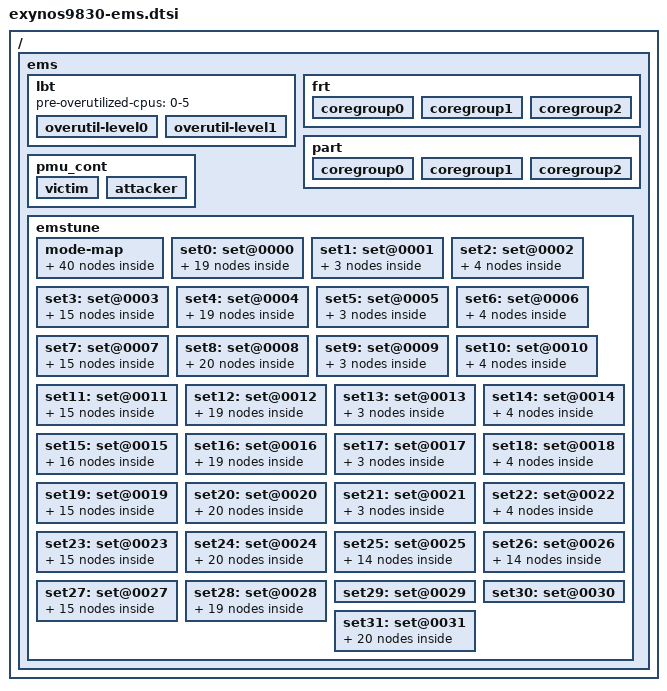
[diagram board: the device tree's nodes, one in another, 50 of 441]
/*
 * SAMSUNG EXYNOS SoC EMS device tree source
 *
 * Copyright (c) 2019 Samsung Electronics Co., Ltd.
 *             http://www.samsung.com
 *
 * SAMSUNG EXYNOS SoC EMS device nodes are listed in this file.
 * EXYNOS based board files should include this file.
 *
 * This program is free software; you can redistribute it and/or modify
 * it under the terms of the GNU General Public License version 2 as
 * published by the Free Software Foundation.
 *
 */
#include <dt-bindings/soc/samsung/ems.h>

/ {
	ems {
		/* Load Balance Trigger */
		#define DEFAULT_RATIO	80
		lbt {
			pre-overutilized-cpus = "0-5";

			overutil-level0 {
				cpus =	"0-3",
					"4-5",
					"6-7";
				ratio =	<25>,
					<25>,
					<30>;
			};
			overutil-level1 {
				cpus = "0-7";
				ratio = <DEFAULT_RATIO>;
			};
		};

		/* FRT Migration */
		frt {
			/* little cores */
			coregroup0 {
				coverage-ratio = <30>;
				active-ratio = <25>;
			};
			/* middle cores */
			coregroup1 {
				coverage-ratio = <30>;
				active-ratio = <100>;
			};
			/* big cores */
			coregroup2 {
				coverage-ratio = <30>;
				active-ratio = <100>;
			};
		};

		part {
			/* little cores */
			coregroup0 {
				active-ratio-limit = <43>;
				active-ratio-boost = <42>;
			};
			/* middle cores */
			coregroup1 {
				active-ratio-limit = <48>;
				active-ratio-boost = <35>;
			};
			/* big cores */
			coregroup2 {
				active-ratio-limit = <30>;
				active-ratio-boost = <0>;
			};
		};

		pmu_cont {
			victim_cpus = "4-5";
			attacker_cpus = "6-7";
			contention_cpus = "0-5";
			attacker_search_timout_msec = <32>;

			victim {
				search_hist_size = <4>;
				event_thr = <850>;
				active_thr = <700>;
			};
			attacker {
				search_hist_size = <1>;
				event_thr = <10>;
				active_thr = <850>;
			};

		};

		emstune {
			mode-map {
				mode0 {
					desc = "normal";
					boost_level = <3>;

					level0 {
						set = <&set0>;
					};
					level1 {
						set = <&set1>;
					};
					level2 {
						set = <&set2>;
					};
					level3 {
						set = <&set3>;
					};
				};
				mode1 {
					desc = "power-scenario";
					boost_level = <3>;

					level0 {
						set = <&set4>;
					};
					level1 {
						set = <&set5>;
					};
					level2 {
						set = <&set6>;
					};
					level3 {
						set = <&set7>;
					};
				};
				mode2 {
					desc = "performance";
					boost_level = <3>;

					level0 {
						set = <&set8>;
					};
					level1 {
						set = <&set9>;
					};
					level2 {
						set = <&set10>;
					};
					level3 {
						set = <&set11>;
					};
				};
				mode3 {
					desc = "light-game";
					boost_level = <3>;

					level0 {
						set = <&set12>;
					};
					level1 {
						set = <&set13>;
					};
					level2 {
						set = <&set14>;
					};
					level3 {
						set = <&set15>;
					};
				};
				mode4 {
					desc = "light-video";
					boost_level = <3>;

					level0 {
						set = <&set16>;
					};
					level1 {
						set = <&set17>;
					};
					level2 {
						set = <&set18>;
					};
					level3 {
						set = <&set19>;
					};
				};
				mode5 {
					desc = "balance";
					boost_level = <3>;

					level0 {
						set = <&set20>;
					};
					level1 {
						set = <&set21>;
					};
					level2 {
						set = <&set22>;
					};
					level3 {
						set = <&set23>;
					};
				};
				mode6 {
					desc = "pinned";
					boost_level = <3>;

					level0 {
						set = <&set24>;
					};
					level1 {
						set = <&set25>;
					};
					level2 {
						set = <&set26>;
					};
					level3 {
						set = <&set27>;
					};
				};
				mode7 {
					desc = "game-mode";
					boost_level = <3>;

					level0 {
						set = <&set28>;
					};
					level1 {
						set = <&set29>;
					};
					level2 {
						set = <&set30>;
					};
					level3 {
						set = <&set31>;
					};
				};

			};

			set0: set@0000{
				idx = <0>;
				desc = "normal default";

				sched_policy {
					policy  = <SCHED_POLICY_EFF		/* root */
						   SCHED_POLICY_EFF		/* fg */
						   SCHED_POLICY_EFF		/* bg */
						   SCHED_POLICY_EFF		/* ta */
						   SCHED_POLICY_EFF>;		/* rt */
				};

				/* weight (%) applied to active cpu's efficiency */
				weight {           /* cpu    0   1   2   3   4   5   6   7 */
					root            = <100 100 100 100 200 200  20  25>;
					foreground      = <100 100 100 100 200 200  20  25>;
					background      = <100 100 100 100 200 200  20  25>;
					top-app         = <100 100 100 100 200 200  20  25>;
					rt              = <100 100 100 100 200 200  20  25>;
				};

				/* weight (%) applied to idle cpu's efficiency */
				idle_weight {      /* cpu    0   1   2   3   4   5   6   7 */
					root            = <200 200 200 200 400 400  40  50>;
					foreground      = <200 200 200 200 400 400  40  50>;
					background      = <200 200 200 200 400 400  40  50>;
					top-app         = <200 200 200 200 400 400  40  50>;
					rt              = <200 200 200 200 400 400  40  50>;
				};

				/* Boosting margin applied to frequency selection */
				freq_boost {       /* cpu    0  1  2  3  4  5  6  7 */
					root            = <  0  0  0  0  0  0  0  0 >;
					foreground      = <  0  0  0  0  0  0  0  0 >;
					background      = <  0  0  0  0  0  0  0  0 >;
					top-app         = <  5  5  5  5  5  5  5  5 >;
					rt              = <  0  0  0  0  0  0  0  0 >;
				};

				/* cpus allowed applied to core selection */
				cpus_allowed {
					target-sched-class = <EMS_SCHED_FAIR>;

					root		= "0-7";
					foreground 	= "0-7";
					background	= "0-7";
					top-app		= "0-7";
					rt		= "0-7";
				};

				/* gov-data used by CPUFreq governor */
				esg {			/* LIT MED BIG */
					step		= <  4   6   8 >;
					patient_mode	= <  0   0   0 >;
				};

				/* Ontime Migration */
				ontime {        /* root fg bg ta rt */
					enabled  = <  0  1  0  1  0  >;

					dom_list_u {
						domain0 {
							cpus = "0-3";
							lower-boundary = <0>;
							upper-boundary = <105>;
						};
						domain1 {
							cpus = "4-5";
							lower-boundary = <106>;
							upper-boundary = <586>;
						};
						domain2 {
							cpus = "6-7";
							lower-boundary = <205>;
							upper-boundary = <1024>;
						};
					};
					dom_list_s {
						domain0 {
							cpus = "0-3";
							lower-boundary = <0>;
							upper-boundary = <51>;
						};
						domain1 {
							cpus = "4-7";
							lower-boundary = <41>;
							upper-boundary = <1024>;
						};
					};
				};
				util_est {	/* root fg bg ta rt */
					enabled  = <  0  1  0  1  0  >;
				};

				prio_pinning {	/* root fg bg ta rt */
					enabled  = <  0  0  0  0  0  >;

					mask = "6-7";
					prio = <110>;
				};

				init_util {	/* root fg bg ta rt */
					ratio  = <   25 25 25 25 25  >;
				};

				frt {	   		/* LIT MED BIG */
					coverage_ratio =  < 30  30  30>;
					active_ratio =	  < 25 100 100>;
				};

				migov {
					migov_en = < 0 >;
				};
			};

			set1: set@0001{
				idx = <1>;
				desc = "normal med boost";

				/* weight (%) applied to active cpu's efficiency */
				weight {           /* cpu    0   1   2   3   4   5   6   7 */
					root            = <100 100 100 100 200 200  20  25>;
					foreground      = < 50  50  50  50 150 150 100 106>;
					background      = <100 100 100 100 200 200  20  25>;
					top-app         = < 50  50  50  50 150 150 100 106>;
					rt              = <100 100 100 100 200 200  20  25>;
				};

				/* weight (%) applied to idle cpu's efficiency */
				idle_weight {      /* cpu    0   1   2   3   4   5   6   7 */
					root            = <200 200 200 200 400 400  40  50>;
					foreground      = <200 200 200 200 7600 7600 3800 4028>;
					background      = <200 200 200 200 400 400  40  50>;
					top-app         = <200 200 200 200 7600 7600 3800 4028>;
					rt              = <200 200 200 200 400 400  40  50>;
				};

				/* Boosting margin applied to frequency selection */
				freq_boost {       /* cpu    0  1  2  3  4  5  6  7 */
					root            = <  0  0  0  0  0  0  0  0 >;
					foreground      = <  0  0  0  0  0  0  0  0 >;
					background      = <  0  0  0  0  0  0  0  0 >;
					top-app         = <  5  5  5  5  5  5  5  5 >;
					rt              = <  0  0  0  0  0  0  0  0 >;
				};
			};

			set2: set@0002{
				idx = <2>;
				desc = "normal touch boost";

				/* weight (%) applied to active cpu's efficiency */
				weight {           /* cpu    0   1   2   3   4   5   6   7 */
					root            = <100 100 100 100 200 200  20  25>;
					foreground      = < 50  50  50  50 150 150 100 106>;
					background      = <100 100 100 100 200 200  20  25>;
					top-app         = < 50  50  50  50 150 150 100 106>;
					rt              = <100 100 100 100 200 200  20  25>;
				};

				/* weight (%) applied to idle cpu's efficiency */
				idle_weight {      /* cpu    0   1   2   3   4   5   6   7 */
					root            = <200 200 200 200 400 400  40  50>;
					foreground      = <200 200 200 200 7600 7600 3800 4028>;
					background      = <200 200 200 200 400 400  40  50>;
					top-app         = <200 200 200 200 7600 7600 3800 4028>;
					rt              = <200 200 200 200 400 400  40  50>;
				};

				/* Boosting margin applied to frequency selection */
				freq_boost {       /* cpu    0  1  2  3  4  5  6  7 */
					root            = <  0  0  0  0  0  0  0  0 >;
					foreground      = <  0  0  0  0  0  0  0  0 >;
					background      = <  0  0  0  0  0  0  0  0 >;
					top-app         = < 20 20 20 20 20 20 20 20 >;
					rt              = <  0  0  0  0  0  0  0  0 >;
				};

				frt {	   		/* LIT MED BIG */
					coverage_ratio =  < 30  30  30>;
					active_ratio =	  < 25   3   5>;
				};
			};

			set3: set@0003{
				idx = <3>;
				desc = "normal big boost";

				sched_policy {
					policy  = <SCHED_POLICY_EFF		/* root */
						   SCHED_POLICY_PERF		/* fg */
						   SCHED_POLICY_EFF		/* bg */
						   SCHED_POLICY_PERF		/* ta */
						   SCHED_POLICY_EFF>;		/* rt */
				};

				/* weight (%) applied to active cpu's efficiency */
				weight {           /* cpu    0   1   2   3   4   5   6   7 */
					root            = <100 100 100 100 100 100 100 100>;
					foreground      = <100 100 100 100 200 200 300 300>;
					background      = <100 100 100 100 100 100 100 100>;
					top-app         = <100 100 100 100 200 200 300 300>;
					rt              = <100 100 100 100 200 200 100 100>;
				};

				/* Boosting margin applied to frequency selection */
				freq_boost {       /* cpu    0  1  2  3  4  5  6  7 */
					root            = <  0  0  0  0  0  0  0  0 >;
					foreground      = <  0  0  0  0  0  0  0  0 >;
					background      = <  0  0  0  0  0  0  0  0 >;
					top-app         = <  5  5  5  5  5  5  5  5 >;
					rt              = <  0  0  0  0  0  0  0  0 >;
				};

				/* Ontime Migration */
				ontime {        /* root fg bg ta rt */
					enabled  = <  0  1  0  1  0  >;

					dom_list_u {
						domain0 {
							cpus = "0-3";
							lower-boundary = <0>;
							upper-boundary = <105>;
						};
						domain1 {
							cpus = "4-5";
							lower-boundary = <106>;
							upper-boundary = <586>;
						};
						domain2 {
							cpus = "6-7";
							lower-boundary = <205>;
							upper-boundary = <1024>;
						};

					};
					dom_list_s {
						domain0 {
							cpus = "0-3";
							lower-boundary = <0>;
							upper-boundary = <51>;
						};
						domain1 {
							cpus = "4-5";
							lower-boundary = <41>;
							upper-boundary = <344>;
						};
						domain2 {
							cpus = "6-7";
							lower-boundary = <300>;
							upper-boundary = <1024>;
						};
					};
				};

				prio_pinning {	/* root fg bg ta rt */
					enabled  = <  0  1  0  1  0  >;

					mask = "6-7";
					prio = <110>;
				};

				init_util {	/* root fg bg ta rt */
					ratio  = <    0  0  0  0  0  >;
				};

				frt {	   		/* LIT MED BIG */
					coverage_ratio =  < 30  30  30>;
					active_ratio =	  < 25   3   5>;
				};
			};

			set4: set@0004{
				idx = <4>;
				desc = "power-scenario default";

				sched_policy {
					policy  = <SCHED_POLICY_ENERGY		/* root */
						   SCHED_POLICY_ENERGY		/* fg */
						   SCHED_POLICY_ENERGY		/* bg */
						   SCHED_POLICY_ENERGY		/* ta */
						   SCHED_POLICY_ENERGY>;	/* rt */
				};

				/* weight (%) applied to active cpu's efficiency */
				weight {           /* cpu    0   1   2   3   4   5   6   7 */
					root            = <1280 1280 1280 1280 200 200  20  25>;
					foreground      = <1280 1280 1280 1280 200 200  20  25>;
					background      = <1280 1280 1280 1280 200 200  20  25>;
					top-app         = <1280 1280 1280 1280 200 200  20  25>;
					rt              = <1280 1280 1280 1280 200 200  20  25>;
				};

				/* weight (%) applied to idle cpu's efficiency */
				idle_weight {      /* cpu    0   1   2   3   4   5   6   7 */
					root            = <2560 2560 2560 2560 400 400  40  50>;
					foreground      = <2560 2560 2560 2560 400 400  40  50>;
					background      = <2560 2560 2560 2560 400 400  40  50>;
					top-app         = <2560 2560 2560 2560 400 400  40  50>;
					rt              = <2560 2560 2560 2560 400 400  40  50>;
				};

				/* Boosting margin applied to frequency selection */
				freq_boost {       /* cpu    0  1  2  3  4  5  6  7 */
					root            = <  0  0  0  0  0  0  0  0 >;
					foreground      = <  0  0  0  0  0  0  0  0 >;
					background      = <  0  0  0  0  0  0  0  0 >;
					top-app         = <  0  0  0  0  0  0  0  0 >;
					rt              = <  0  0  0  0  0  0  0  0 >;
				};

				/* cpus allowed applied to core selection */
				cpus_allowed {
					target-sched-class = <EMS_SCHED_FAIR>;

					root		= "0-7";
					foreground 	= "0-7";
					background	= "0-7";
					top-app		= "0-7";
					rt		= "0-7";
				};

				/* gov-data used by CPUFreq governor */
				esg {		/* LIT MED BIG */
					step		= < 10   8  10>;
					patient_mode	= <  0   0  0 >;
				};

				/* Ontime Migration */
				ontime {        /* root fg bg ta rt */
					enabled  = <  0  1  0  1  0  >;

					dom_list_u {
						domain0 {
							cpus = "0-3";
							lower-boundary = <0>;
							upper-boundary = <105>;
						};
						domain1 {
							cpus = "4-5";
							lower-boundary = <106>;
							upper-boundary = <586>;
						};
						domain2 {
							cpus = "6-7";
							lower-boundary = <205>;
							upper-boundary = <1024>;
						};
					};
					dom_list_s {
						domain0 {
							cpus = "0-3";
							lower-boundary = <0>;
							upper-boundary = <51>;
						};
						domain1 {
							cpus = "4-7";
							lower-boundary = <41>;
							upper-boundary = <1024>;
						};
					};
				};

				util_est {	/* root fg bg ta rt */
					enabled  = <  0  1  0  1  0  >;
				};

				prio_pinning {	/* root fg bg ta rt */
					enabled  = <  0  0  0  0  0  >;

					mask = "6-7";
					prio = <110>;
				};

				init_util {	/* root fg bg ta rt */
					ratio  = <   25 25 25 25 25  >;
				};

				frt {	   		/* LIT MED BIG */
					coverage_ratio =  < 30  30  30>;
					active_ratio =	  < 25 100 100>;
				};

				migov {
					migov_en = < 0 >;
				};
			};

			set5: set@0005{
				idx = <5>;
				desc = "power-scenario med boost";

				/* weight (%) applied to active cpu's efficiency */
				weight {           /* cpu    0   1   2   3   4   5   6   7 */
					root            = <1280 1280 1280 1280 200 200  20  25>;
					foreground      = < 50  50  50  50 150 150 100 106>;
					background      = <1280 1280 1280 1280 200 200  20  25>;
					top-app         = < 50  50  50  50 150 150 100 106>;
					rt              = <1280 1280 1280 1280 200 200  20  25>;
				};

				/* weight (%) applied to idle cpu's efficiency */
				idle_weight {      /* cpu    0   1   2   3   4   5   6   7 */
					root            = <2560 2560 2560 2560 400 400  40  50>;
					foreground      = <200 200 200 200 7600 7600 3800 4028>;
					background      = <2560 2560 2560 2560 400 400  40  50>;
					top-app         = <200 200 200 200 7600 7600 3800 4028>;
					rt              = <2560 2560 2560 2560 400 400  40  50>;
				};

				/* Boosting margin applied to frequency selection */
				freq_boost {       /* cpu    0  1  2  3  4  5  6  7 */
					root            = <  0  0  0  0  0  0  0  0 >;
					foreground      = <  0  0  0  0  0  0  0  0 >;
					background      = <  0  0  0  0  0  0  0  0 >;
					top-app         = <  0  0  0  0  0  0  0  0 >;
					rt              = <  0  0  0  0  0  0  0  0 >;
				};
			};

			set6: set@0006{
				idx = <6>;
				desc = "power-scenario touch boost";

				/* weight (%) applied to active cpu's efficiency */
				weight {           /* cpu    0   1   2   3   4   5   6   7 */
					root            = <1280 1280 1280 1280 200 200  20  25>;
					foreground      = < 50  50  50  50 150 150 100 106>;
					background      = <1280 1280 1280 1280 200 200  20  25>;
					top-app         = < 50  50  50  50 150 150 100 106>;
					rt              = <1280 1280 1280 1280 200 200  20  25>;
				};

				/* weight (%) applied to idle cpu's efficiency */
				idle_weight {      /* cpu    0   1   2   3   4   5   6   7 */
					root            = <2560 2560 2560 2560 400 400  40  50>;
					foreground      = <200 200 200 200 7600 7600 3800 4028>;
					background      = <2560 2560 2560 2560 400 400  40  50>;
					top-app         = <200 200 200 200 7600 7600 3800 4028>;
					rt              = <2560 2560 2560 2560 400 400  40  50>;
				};

				/* Boosting margin applied to frequency selection */
				freq_boost {       /* cpu    0  1  2  3  4  5  6  7 */
					root            = <  0  0  0  0  0  0  0  0 >;
					foreground      = <  0  0  0  0  0  0  0  0 >;
					background      = <  0  0  0  0  0  0  0  0 >;
					top-app         = <  0  0  0  0  0  0  0  0 >;
					rt              = <  0  0  0  0  0  0  0  0 >;
				};

				frt {	   		/* LIT MED BIG */
					coverage_ratio =  < 30  30  30>;
					active_ratio =	  < 25   3   5>;
				};
			};

			set7: set@0007{
				idx = <7>;
				desc = "power-scenario big boost";

				sched_policy {
					policy  = <SCHED_POLICY_EFF		/* root */
						   SCHED_POLICY_PERF		/* fg */
						   SCHED_POLICY_EFF		/* bg */
						   SCHED_POLICY_PERF		/* ta */
						   SCHED_POLICY_EFF>;		/* rt */
				};

				/* weight (%) applied to active cpu's efficiency */
				weight {           /* cpu    0   1   2   3   4   5   6   7 */
					root            = <100 100 100 100 100 100 100 100>;
					foreground      = <100 100 100 100 200 200 300 300>;
					background      = <100 100 100 100 100 100 100 100>;
					top-app         = <100 100 100 100 200 200 300 300>;
					rt              = <100 100 100 100 200 200 100 100>;
				};

				/* Boosting margin applied to frequency selection */
				freq_boost {       /* cpu    0  1  2  3  4  5  6  7 */
					root            = <  0  0  0  0  0  0  0  0 >;
					foreground      = <  0  0  0  0  0  0  0  0 >;
					background      = <  0  0  0  0  0  0  0  0 >;
					top-app         = <  0  0  0  0  0  0  0  0 >;
					rt              = <  0  0  0  0  0  0  0  0 >;
				};

				/* Ontime Migration */
				ontime {        /* root fg bg ta rt */
					enabled  = <  0  1  0  1  0  >;

					dom_list_u {
						domain0 {
							cpus = "0-3";
							lower-boundary = <0>;
							upper-boundary = <105>;
						};
						domain1 {
							cpus = "4-5";
							lower-boundary = <106>;
							upper-boundary = <586>;
						};
						domain2 {
							cpus = "6-7";
							lower-boundary = <205>;
							upper-boundary = <1024>;
						};

					};
					dom_list_s {
						domain0 {
							cpus = "0-3";
							lower-boundary = <0>;
							upper-boundary = <51>;
						};
						domain1 {
							cpus = "4-5";
							lower-boundary = <41>;
							upper-boundary = <344>;
						};
						domain2 {
							cpus = "6-7";
							lower-boundary = <300>;
							upper-boundary = <1024>;
						};
					};
				};

				prio_pinning {	/* root fg bg ta rt */
					enabled  = <  0  1  0  1  0  >;

					mask = "6-7";
					prio = <110>;
				};

				init_util {	/* root fg bg ta rt */
					ratio  = <    0  0  0  0  0  >;
				};

				frt {	   		/* LIT MED BIG */
					coverage_ratio =  < 30  30  30>;
					active_ratio =	  < 25   3   5>;
				};
			};

			set8: set@0008{
				idx = <8>;
				desc = "performance default";

				sched_policy {
					policy  = <SCHED_POLICY_EFF		/* root */
						   SCHED_POLICY_EFF		/* fg */
						   SCHED_POLICY_EFF		/* bg */
						   SCHED_POLICY_EFF		/* ta */
						   SCHED_POLICY_EFF>;		/* rt */
				};

				/* weight (%) applied to active cpu's efficiency */
				weight {           /* cpu    0   1   2   3   4   5   6   7 */
					root            = <100 100 100 100 200 200  20  25>;
					foreground      = <100 100 100 100 200 200  20  25>;
					background      = <100 100 100 100 200 200  20  25>;
					top-app         = <100 100 100 100 200 200  20  25>;
					rt              = <100 100 100 100 200 200  20  25>;
				};

				/* weight (%) applied to idle cpu's efficiency */
				idle_weight {      /* cpu    0   1   2   3   4   5   6   7 */
					root            = <200 200 200 200 400 400  40  50>;
					foreground      = <200 200 200 200 400 400  40  50>;
					background      = <200 200 200 200 400 400  40  50>;
					top-app         = <200 200 200 200 400 400  40  50>;
					rt              = <200 200 200 200 400 400  40  50>;
				};

				/* Boosting margin applied to frequency selection */
				freq_boost {       /* cpu    0  1  2  3  4  5  6  7 */
					root            = <  0  0  0  0  0  0  0  0 >;
					foreground      = <  0  0  0  0  0  0  0  0 >;
					background      = <  0  0  0  0  0  0  0  0 >;
					top-app         = < 80 80 80 80 80 80  5  5 >;
					rt              = <  0  0  0  0  0  0  0  0 >;
				};

				/* cpus allowed applied to core selection */
				cpus_allowed {
					target-sched-class = <EMS_SCHED_FAIR>;

					root		= "0-7";
					foreground 	= "0-7";
					background	= "0-7";
					top-app		= "0-7";
					rt		= "0-7";
				};

				/* gov-data used by CPUFreq governor */
				esg {			/* LIT MED BIG */
					step		= <  4   2   8 >;
					patient_mode	= <  0   0  0 >;
				};

				/* Ontime Migration */
				ontime {        /* root fg bg ta rt */
					enabled  = <  0  1  0  1  0  >;

					dom_list_u {
						domain0 {
							cpus = "0-3";
							lower-boundary = <0>;
							upper-boundary = <105>;
						};
						domain1 {
							cpus = "4-5";
							lower-boundary = <106>;
							upper-boundary = <586>;
						};
						domain2 {
							cpus = "6-7";
							lower-boundary = <205>;
							upper-boundary = <1024>;
						};
					};
					dom_list_s {
						domain0 {
							cpus = "0-3";
							lower-boundary = <0>;
							upper-boundary = <51>;
						};
						domain1 {
							cpus = "4-5";
							lower-boundary = <41>;
							upper-boundary = <344>;
						};
						domain2 {
							cpus = "6-7";
							lower-boundary = <300>;
							upper-boundary = <1024>;
						};
					};
				};

				util_est {	/* root fg bg ta rt */
					enabled  = <  0  1  0  1  0  >;
				};

				prio_pinning {	/* root fg bg ta rt */
					enabled  = <  0  0  0  0  0  >;

					mask = "6-7";
					prio = <110>;
				};

				init_util {	/* root fg bg ta rt */
					ratio  = <   25 25 25 25 25  >;
				};

				frt {	   		/* LIT MED BIG */
					coverage_ratio =  < 30  30  30>;
					active_ratio =	  < 25 100 100>;
				};
				migov {
					migov_en = < 0 >;
				};
			};

			set9: set@0009{
				idx = <9>;
				desc = "performance med boost";

				/* weight (%) applied to active cpu's efficiency */
				weight {           /* cpu    0   1   2   3   4   5   6   7 */
					root            = <100 100 100 100 200 200  20  25>;
					foreground      = < 50  50  50  50 150 150 100 106>;
					background      = <100 100 100 100 200 200  20  25>;
					top-app         = < 50  50  50  50 150 150 100 106>;
					rt              = <100 100 100 100 200 200  20  25>;
				};

				/* weight (%) applied to idle cpu's efficiency */
				idle_weight {      /* cpu    0   1   2   3   4   5   6   7 */
					root            = <200 200 200 200 400 400  40  50>;
					foreground      = <200 200 200 200 7600 7600 3800 4028>;
					background      = <200 200 200 200 400 400  40  50>;
					top-app         = <200 200 200 200 7600 7600 3800 4028>;
					rt              = <200 200 200 200 400 400  40  50>;
				};

				/* Boosting margin applied to frequency selection */
				freq_boost {       /* cpu    0  1  2  3  4  5  6  7 */
					root            = <  0  0  0  0  0  0  0  0 >;
					foreground      = <  0  0  0  0  0  0  0  0 >;
					background      = <  0  0  0  0  0  0  0  0 >;
					top-app         = < 80 80 80 80 80 80  5  5 >;
					rt              = <  0  0  0  0  0  0  0  0 >;
				};
			};

			set10: set@0010{
				idx = <10>;
				desc = "performance touch boost";

				/* weight (%) applied to active cpu's efficiency */
				weight {           /* cpu    0   1   2   3   4   5   6   7 */
					root            = <100 100 100 100 200 200  20  25>;
					foreground      = < 50  50  50  50 150 150 100 106>;
					background      = <100 100 100 100 200 200  20  25>;
					top-app         = < 50  50  50  50 150 150 100 106>;
					rt              = <100 100 100 100 200 200  20  25>;
				};

				/* weight (%) applied to idle cpu's efficiency */
				idle_weight {      /* cpu    0   1   2   3   4   5   6   7 */
					root            = <200 200 200 200 400 400  40  50>;
					foreground      = <200 200 200 200 7600 7600 3800 4028>;
					background      = <200 200 200 200 400 400  40  50>;
					top-app         = <200 200 200 200 7600 7600 3800 4028>;
					rt              = <200 200 200 200 400 400  40  50>;
				};

				/* Boosting margin applied to frequency selection */
				freq_boost {       /* cpu    0  1  2  3  4  5  6  7 */
					root            = <  0  0  0  0  0  0  0  0 >;
					foreground      = <  0  0  0  0  0  0  0  0 >;
					background      = <  0  0  0  0  0  0  0  0 >;
					top-app         = < 80 80 80 80 80 80 20 20 >;
					rt              = <  0  0  0  0  0  0  0  0 >;
				};

				frt {	   		/* LIT MED BIG */
					coverage_ratio =  < 30  30  30>;
					active_ratio =	  < 25   3   5>;
				};
			};

			set11: set@0011{
				idx = <11>;
				desc = "performance big boost";

				sched_policy {
					policy  = <SCHED_POLICY_EFF		/* root */
						   SCHED_POLICY_PERF		/* fg */
						   SCHED_POLICY_EFF		/* bg */
						   SCHED_POLICY_PERF		/* ta */
						   SCHED_POLICY_EFF>;		/* rt */
				};

				/* weight (%) applied to active cpu's efficiency */
				weight {           /* cpu    0   1   2   3   4   5   6   7 */
					root            = <100 100 100 100 100 100 100 100>;
					foreground      = <100 100 100 100 200 200 300 300>;
					background      = <100 100 100 100 100 100 100 100>;
					top-app         = <100 100 100 100 200 200 300 300>;
					rt              = <100 100 100 100 200 200 100 100>;
				};

				/* Boosting margin applied to frequency selection */
				freq_boost {       /* cpu    0  1  2  3  4  5  6  7 */
					root            = <  0  0  0  0  0  0  0  0 >;
					foreground      = <  0  0  0  0  0  0  0  0 >;
					background      = <  0  0  0  0  0  0  0  0 >;
					top-app         = < 80 80 80 80 80 80  5  5 >;
					rt              = <  0  0  0  0  0  0  0  0 >;
				};

				/* Ontime Migration */
				ontime {        /* root fg bg ta rt */
					enabled  = <  0  1  0  1  0  >;

					dom_list_u {
						domain0 {
							cpus = "0-3";
							lower-boundary = <0>;
							upper-boundary = <105>;
						};
						domain1 {
							cpus = "4-5";
							lower-boundary = <106>;
							upper-boundary = <586>;
						};
						domain2 {
							cpus = "6-7";
							lower-boundary = <205>;
							upper-boundary = <1024>;
						};

					};
					dom_list_s {
						domain0 {
							cpus = "0-3";
							lower-boundary = <0>;
							upper-boundary = <51>;
						};
						domain1 {
							cpus = "4-5";
							lower-boundary = <41>;
							upper-boundary = <344>;
						};
						domain2 {
							cpus = "6-7";
							lower-boundary = <300>;
							upper-boundary = <1024>;
						};
					};
				};

				prio_pinning {	/* root fg bg ta rt */
					enabled  = <  0  1  0  1  0  >;

					mask = "6-7";
					prio = <110>;
				};

				init_util {	/* root fg bg ta rt */
					ratio  = <    0  0  0  0  0  >;
				};

				frt {	   		/* LIT MED BIG */
					coverage_ratio =  < 30  30  30>;
					active_ratio =	  < 25   3   5>;
				};
			};

			set12: set@0012{
				idx = <12>;
				desc = "light-game default";

				sched_policy {
					policy  = <SCHED_POLICY_EFF		/* root */
						   SCHED_POLICY_EFF		/* fg */
						   SCHED_POLICY_EFF		/* bg */
						   SCHED_POLICY_EFF		/* ta */
						   SCHED_POLICY_EFF>;		/* rt */
				};

				/* weight (%) applied to active cpu's efficiency */
				weight {           /* cpu    0   1   2   3   4   5   6   7 */
					root            = <1280 1280 1280 1280 200 200  20  25>;
					foreground      = <1280 1280 1280 1280 200 200  20  25>;
					background      = <1280 1280 1280 1280 200 200  20  25>;
					top-app         = <1280 1280 1280 1280 200 200  20  25>;
					rt              = <1280 1280 1280 1280 200 200  20  25>;
				};

				/* weight (%) applied to idle cpu's efficiency */
				idle_weight {      /* cpu     0    1    2    3   4   5   6   7 */
					root            = <2560 2560 2560 2560 400 400  40  50>;
					foreground      = <2560 2560 2560 2560 400 400  40  50>;
					background      = <2560 2560 2560 2560 400 400  40  50>;
					top-app         = <2560 2560 2560 2560 400 400  40  50>;
					rt              = <2560 2560 2560 2560 400 400  40  50>;
				};

				/* Boosting margin applied to frequency selection */
				freq_boost {       /* cpu    0  1  2  3  4  5  6  7 */
					root            = < (-20) (-20) (-20) (-20) (-30) (-30) (-20) (-20) >;
					foreground      = < (-20) (-20) (-20) (-20) (-30) (-30) (-20) (-20) >;
					background      = < (-20) (-20) (-20) (-20) (-30) (-30) (-20) (-20) >;
					top-app         = < (-20) (-20) (-20) (-20) (-30) (-30) (-20) (-20) >;
					rt              = < (-20) (-20) (-20) (-20) (-30) (-30) (-20) (-20) >;
				};

				/* cpus allowed applied to core selection */
				cpus_allowed {
					target-sched-class = <EMS_SCHED_FAIR>;

					root		= "0-7";
					foreground 	= "0-7";
					background	= "0-7";
					top-app		= "0-7";
					rt		= "0-7";
				};

				/* gov-data used by CPUFreq governor */
				esg {		/* LIT MED BIG */
					step		= < 4  6  8>;
					patient_mode	= < 0  0  0>;
				};

				/* Ontime Migration */
				ontime {        /* root fg bg ta rt */
					enabled  = <  0  1  0  1  0  >;

					dom_list_u {
						domain0 {
							cpus = "0-3";
							lower-boundary = <0>;
							upper-boundary = <105>;
						};
						domain1 {
							cpus = "4-5";
							lower-boundary = <106>;
							upper-boundary = <733>;
						};
						domain2 {
							cpus = "6-7";
							lower-boundary = <768>;
							upper-boundary = <1024>;
						};
					};
					dom_list_s {
						domain0 {
							cpus = "0-3";
							lower-boundary = <0>;
							upper-boundary = <51>;
						};
						domain1 {
							cpus = "4-7";
							lower-boundary = <41>;
							upper-boundary = <1024>;
						};
					};
				};

				util_est {	/* root fg bg ta rt */
					enabled  = <  0  1  0  1  0  >;
				};

				prio_pinning {	/* root fg bg ta rt */
					enabled  = <  0  0  0  0  0  >;

					mask = "6-7";
					prio = <110>;
				};

				init_util {	/* root fg bg ta rt */
					ratio  = <   25 25 25 25 25  >;
				};

				frt {	   		/* LIT MED BIG */
					coverage_ratio =  < 30  30  30>;
					active_ratio =	  < 25 100 100>;
				};

				migov {
					migov_en = < 0 >;
				};
			};

			set13: set@0013{
				idx = <13>;
				desc = "light-game med boost";

				/* weight (%) applied to active cpu's efficiency */
				weight {           /* cpu    0   1   2   3   4   5   6   7 */
					root            = <1280 1280 1280 1280 200 200  20  25>;
					foreground      = <100 100 100 100 300 300 200 212>;
					background      = <1280 1280 1280 1280 200 200  20  25>;
					top-app         = <100 100 100 100 300 300 200 212>;
					rt              = <1280 1280 1280 1280 200 200  20  25>;
				};

				/* weight (%) applied to idle cpu's efficiency */
				idle_weight {      /* cpu     0    1    2    3   4   5   6   7 */
					root            = <2560 2560 2560 2560 400 400  40  50>;
					foreground      = < 125  125  125  125  600 600 300  318>;
					background      = <2560 2560 2560 2560 400 400  40  50>;
					top-app         = < 125  125  125  125  600 600 300  318>;
					rt              = <2560 2560 2560 2560 400 400  40  50>;
				};

				freq_boost {       /* cpu    0  1  2  3  4  5  6  7 */
					root            = < (-20) (-20) (-20) (-20) (-30) (-30) (-20) (-20) >;
					foreground      = < (-20) (-20) (-20) (-20) (-30) (-30) (-20) (-20) >;
					background      = < (-20) (-20) (-20) (-20) (-30) (-30) (-20) (-20) >;
					top-app         = < (-20) (-20) (-20) (-20) (-30) (-30) (-20) (-20) >;
					rt              = < (-20) (-20) (-20) (-20) (-30) (-30) (-20) (-20) >;
				};
			};

			set14: set@0014{
				idx = <14>;
				desc = "light-game touch boost";

				/* weight (%) applied to active cpu's efficiency */
				weight {           /* cpu    0   1   2   3   4   5   6   7 */
					root            = <1280 1280 1280 1280 200 200  20  25>;
					foreground      = <100 100 100 100 300 300 200 212>;
					background      = <1280 1280 1280 1280 200 200  20  25>;
					top-app         = <100 100 100 100 300 300 200 212>;
					rt              = <1280 1280 1280 1280 200 200  20  25>;
				};

				/* weight (%) applied to idle cpu's efficiency */
				idle_weight {      /* cpu     0    1    2    3   4   5   6   7 */
					root            = <2560 2560 2560 2560 400 400  40  50>;
					foreground      = < 125  125  125  125  600 600 300  318>;
					background      = <2560 2560 2560 2560 400 400  40  50>;
					top-app         = < 125  125  125  125  600 600 300  318>;
					rt              = <2560 2560 2560 2560 400 400  40  50>;
				};

				freq_boost {       /* cpu    0  1  2  3  4  5  6  7 */
					root            = < (-20) (-20) (-20) (-20) (-30) (-30) (-20) (-20) >;
					foreground      = < (-20) (-20) (-20) (-20) (-30) (-30) (-20) (-20) >;
					background      = < (-20) (-20) (-20) (-20) (-30) (-30) (-20) (-20) >;
					top-app         = < (-20) (-20) (-20) (-20) (-30) (-30) (-20) (-20) >;
					rt              = < (-20) (-20) (-20) (-20) (-30) (-30) (-20) (-20) >;
				};

				frt {	   		/* LIT MED BIG */
					coverage_ratio =  < 30  30  30>;
					active_ratio =	  < 25   3   5>;
				};
			};

			set15: set@0015{
				idx = <15>;
				desc = "light-game big boost";

				sched_policy {
					policy  = <SCHED_POLICY_EFF		/* root */
						   SCHED_POLICY_PERF		/* fg */
						   SCHED_POLICY_EFF		/* bg */
						   SCHED_POLICY_PERF		/* ta */
						   SCHED_POLICY_EFF>;		/* rt */
				};

				/* weight (%) applied to active cpu's efficiency */
				weight {           /* cpu    0   1   2   3   4   5   6   7 */
					root            = <1280 1280 1280 1280 200 200 20 25>;
					foreground      = <100 100 100 100 200 200 300 300>;
					background      = <1280 1280 1280 1280 200 200 20 25>;
					top-app         = <100 100 100 100 200 200 300 300>;
					rt              = <1280 1280 1280 1280 200 200 20 25>;
				};

				/* weight (%) applied to idle cpu's efficiency */
				idle_weight {      /* cpu    0   1   2   3   4   5   6   7 */
					root            = <2560 2560 2560 2560 400 400  40  50>;
					foreground      = <200 200 200 200 400 400  40  50>;
					background      = <2560 2560 2560 2560 400 400  40  50>;
					top-app         = <200 200 200 200 400 400  40  50>;
					rt              = <2560 2560 2560 2560 400 400  40  50>;
				};

				/* Boosting margin applied to frequency selection */
				freq_boost {       /* cpu    0  1  2  3  4  5  6  7 */
					root            = <  0  0  0  0  0  0  0  0 >;
					foreground      = <  0  0  0  0  0  0  0  0 >;
					background      = <  0  0  0  0  0  0  0  0 >;
					top-app         = <  0  0  0  0  0  0  0  0 >;
					rt              = <  0  0  0  0  0  0  0  0 >;
				};

				/* Ontime Migration */
				ontime {        /* root fg bg ta rt */
					enabled  = <  0  1  0  1  0  >;

					dom_list_u {
						domain0 {
							cpus = "0-3";
							lower-boundary = <0>;
							upper-boundary = <105>;
						};
						domain1 {
							cpus = "4-5";
							lower-boundary = <106>;
							upper-boundary = <586>;
						};
						domain2 {
							cpus = "6-7";
							lower-boundary = <205>;
							upper-boundary = <1024>;
						};

					};
					dom_list_s {
						domain0 {
							cpus = "0-3";
							lower-boundary = <0>;
							upper-boundary = <51>;
						};
						domain1 {
							cpus = "4-5";
							lower-boundary = <41>;
							upper-boundary = <344>;
						};
						domain2 {
							cpus = "6-7";
							lower-boundary = <300>;
							upper-boundary = <1024>;
						};
					};
				};

				prio_pinning {	/* root fg bg ta rt */
					enabled  = <  0  1  0  1  0  >;

					mask = "6-7";
					prio = <110>;
				};

				init_util {	/* root fg bg ta rt */
					ratio  = <    0  0  0  0  0  >;
				};

				frt {	   		/* LIT MED BIG */
					coverage_ratio =  < 30  30  30>;
					active_ratio =	  < 25   3   5>;
				};
			};

			set16: set@0016{
				idx = <16>;
				desc = "light-video default";

				sched_policy {
					policy  = <SCHED_POLICY_EFF		/* root */
						   SCHED_POLICY_EFF		/* fg */
						   SCHED_POLICY_EFF		/* bg */
						   SCHED_POLICY_EFF		/* ta */
						   SCHED_POLICY_EFF>;		/* rt */
				};

				/* weight (%) applied to active cpu's efficiency */
				weight {           /* cpu    0   1   2   3   4   5   6   7 */
					root            = <1280 1280 1280 100 100 100  20  25>;
					foreground      = <1280 1280 1280 100 100 100  20  25>;
					background      = <1280 1280 1280 100 100 100  20  25>;
					top-app         = <1280 1280 1280 1600 100 100  20  25>;
					rt              = <1280 1280 1280 100 100 100  20  25>;
				};

				/* weight (%) applied to idle cpu's efficiency */
				idle_weight {      /* cpu    0   1   2   3   4   5   6   7 */
					root            = <1500 1500 1500 125 125 125  40  50>;
					foreground      = <1500 1500 1500 125 125 125  40  50>;
					background      = <1500 1500 1500 125 125 125  40  50>;
					top-app         = <1500 1500 1500 2000 125 125  40  50>;
					rt              = <1500 1500 1500 125 125 125  40  50>;
				};

				/* Boosting margin applied to frequency selection */
				freq_boost {       /* cpu    0  1  2  3  4  5  6  7 */
					root            = < (-50) (-50) (-50) (-50) 0 0 0 0>;
					foreground      = < (-50) (-50) (-50) (-50) 0 0 0 0>;
					background      = < (-50) (-50) (-50) (-50) 0 0 0 0>;
					top-app         = < (-50) (-50) (-50) (-30) 0 0 0 0>;
					rt              = < (-50) (-50) (-50) (-50) 0 0 0 0>;
				};

				/* cpus allowed applied to core selection */
				cpus_allowed {
					target-sched-class = <EMS_SCHED_FAIR>;

					root		= "0-7";
					foreground 	= "0-7";
					background	= "0-7";
					top-app		= "0-7";
					rt		= "0-7";
				};

				/* gov-data used by CPUFreq governor */
				esg {		/* LIT MED BIG */
					step		= < 10  8  10>;
					patient_mode	= < 0  0  0>;
				};

				/* Ontime Migration */
				ontime {        /* root fg bg ta rt */
					enabled  = <  0  1  0  1  0  >;

					dom_list_u {
						domain0 {
							cpus = "0-3";
							lower-boundary = <0>;
							upper-boundary = <105>;
						};
						domain1 {
							cpus = "4-5";
							lower-boundary = <106>;
							upper-boundary = <586>;
						};
						domain2 {
							cpus = "6-7";
							lower-boundary = <205>;
							upper-boundary = <1024>;
						};
					};
					dom_list_s {
						domain0 {
							cpus = "0-3";
							lower-boundary = <0>;
							upper-boundary = <51>;
						};
						domain1 {
							cpus = "4-7";
							lower-boundary = <41>;
							upper-boundary = <1024>;
						};
					};
				};

				util_est {	/* root fg bg ta rt */
					enabled  = <  0  1  0  1  0  >;
				};

				prio_pinning {	/* root fg bg ta rt */
					enabled  = <  0  0  0  0  0  >;

					mask = "6-7";
					prio = <110>;
				};

				init_util {	/* root fg bg ta rt */
					ratio  = <   25 25 25 25 25  >;
				};

				frt {	   		/* LIT MED BIG */
					coverage_ratio =  < 30  30  30>;
					active_ratio =	  < 25 100 100>;
				};

				migov {
					migov_en = < 0 >;
				};
			};

			set17: set@0017{
				idx = <17>;
				desc = "light-video med boost";

				/* weight (%) applied to active cpu's efficiency */
				weight {           /* cpu    0   1   2   3   4   5   6   7 */
					root            = <1280 1280 1280 1280 100 100  20  25>;
					foreground      = <50 50 50 50 150 150  100 106>;
					background      = <1280 1280 1280 1280 100 100  20  25>;
					top-app			= <50 50 50 50 150 150  100 106>;
					rt              = <1280 1280 1280 1280 100 100  20  25>;
				};

				/* weight (%) applied to idle cpu's efficiency */
				idle_weight {      /* cpu    0   1   2   3   4   5   6   7 */
					root            = <1500 1500 1500 1500 125 125  40  50>;
					foreground      = <200 200 200 200 7600 7600 3800 4028>;
					background      = <1500 1500 1500 1500 125 125  40  50>;
					top-app			= <200 200 200 200 7600 7600 3800 4028>;
					rt              = <1500 1500 1500 1500 125 125  40  50>;
				};

				freq_boost {       /* cpu    0  1  2  3  4  5  6  7 */
					root            = <  0  0  0  0  0  0  0  0 >;
					foreground      = <  0  0  0  0  0  0  0  0 >;
					background      = <  0  0  0  0  0  0  0  0 >;
					top-app         = <  0  0  0  0  0  0  0  0 >;
					rt              = <  0  0  0  0  0  0  0  0 >;
				};
			};

			set18: set@0018{
				idx = <18>;
				desc = "light-video touch boost";

				/* weight (%) applied to active cpu's efficiency */
				weight {           /* cpu    0   1   2   3   4   5   6   7 */
					root            = <1280 1280 1280 1280 100 100  20  25>;
					foreground      = <50 50 50 50 150 150  100 106>;
					background      = <1280 1280 1280 1280 100 100  20  25>;
					top-app			= <50 50 50 50 150 150  100 106>;
					rt              = <1280 1280 1280 1280 100 100  20  25>;
				};

				/* weight (%) applied to idle cpu's efficiency */
				idle_weight {      /* cpu    0   1   2   3   4   5   6   7 */
					root            = <1500 1500 1500 1500 125 125  40  50>;
					foreground      = <200 200 200 200 7600 7600 3800 4028>;
					background      = <1500 1500 1500 1500 125 125  40  50>;
					top-app			= <200 200 200 200 7600 7600 3800 4028>;
					rt              = <1500 1500 1500 1500 125 125  40  50>;
				};

				freq_boost {       /* cpu    0  1  2  3  4  5  6  7 */
					root            = <  0  0  0  0  0  0  0  0 >;
					foreground      = <  0  0  0  0  0  0  0  0 >;
					background      = <  0  0  0  0  0  0  0  0 >;
					top-app         = <  0  0  0  0  0  0  0  0 >;
					rt              = <  0  0  0  0  0  0  0  0 >;
				};

				frt {	   		/* LIT MED BIG */
					coverage_ratio =  < 30  30  30>;
					active_ratio =	  < 25   3   5>;
				};
			};

			set19: set@0019{
				idx = <19>;
				desc = "light-video big boost";

				sched_policy {
					policy  = <SCHED_POLICY_EFF		/* root */
						   SCHED_POLICY_PERF		/* fg */
						   SCHED_POLICY_EFF		/* bg */
						   SCHED_POLICY_PERF		/* ta */
						   SCHED_POLICY_EFF>;		/* rt */
				};

				/* weight (%) applied to active cpu's efficiency */
				weight {           /* cpu    0   1   2   3   4   5   6   7 */
					root            = <100 100 100 100 100 100 100 100>;
					foreground      = <100 100 100 100 200 200 300 300>;
					background      = <100 100 100 100 100 100 100 100>;
					top-app         = <100 100 100 100 200 200 300 300>;
					rt              = <100 100 100 100 200 200 100 100>;
				};

				freq_boost {       /* cpu    0  1  2  3  4  5  6  7 */
					root            = <  0  0  0  0  0  0  0  0 >;
					foreground      = <  0  0  0  0  0  0  0  0 >;
					background      = <  0  0  0  0  0  0  0  0 >;
					top-app         = <  0  0  0  0  0  0  0  0 >;
					rt              = <  0  0  0  0  0  0  0  0 >;
				};

				/* Ontime Migration */
				ontime {        /* root fg bg ta rt */
					enabled  = <  0  1  0  1  0  >;

					dom_list_u {
						domain0 {
							cpus = "0-3";
							lower-boundary = <0>;
							upper-boundary = <105>;
						};
						domain1 {
							cpus = "4-5";
							lower-boundary = <106>;
							upper-boundary = <586>;
						};
						domain2 {
							cpus = "6-7";
							lower-boundary = <205>;
							upper-boundary = <1024>;
						};

					};
					dom_list_s {
						domain0 {
							cpus = "0-3";
							lower-boundary = <0>;
							upper-boundary = <51>;
						};
						domain1 {
							cpus = "4-5";
							lower-boundary = <41>;
							upper-boundary = <344>;
						};
						domain2 {
							cpus = "6-7";
							lower-boundary = <300>;
							upper-boundary = <1024>;
						};
					};
				};

				prio_pinning {	/* root fg bg ta rt */
					enabled  = <  0  1  0  1  0  >;

					mask = "6-7";
					prio = <110>;
				};

				init_util {	/* root fg bg ta rt */
					ratio  = <    0  0  0  0  0  >;
				};

				frt {	   		/* LIT MED BIG */
					coverage_ratio =  < 30  30  30>;
					active_ratio =	  < 25   3   5>;
				};
			};

			set20: set@0020{
				idx = <20>;
				desc = "balance default";

				sched_policy {
					policy  = <SCHED_POLICY_EFF		/* root */
						   SCHED_POLICY_EFF		/* fg */
						   SCHED_POLICY_EFF		/* bg */
						   SCHED_POLICY_EFF		/* ta */
						   SCHED_POLICY_EFF>;		/* rt */
				};

				/* weight (%) applied to active cpu's efficiency */
				weight {           /* cpu    0   1   2   3   4   5   6   7 */
					root            = <200 200 200 200 100 100  20  25>;
					foreground      = <200 200 200 200 100 100  20  25>;
					background      = <200 200 200 200 100 100  20  25>;
					top-app         = <200 200 200 200 100 100  20  25>;
					rt              = <200 200 200 200 100 100  20  25>;
				};

				/* weight (%) applied to idle cpu's efficiency */
				idle_weight {      /* cpu     0    1    2    3   4   5   6   7 */
					root            = <400 400 400 400 200 200  20  25>;
					foreground      = <400 400 400 400 200 200  20  25>;
					background      = <400 400 400 400 200 200  20  25>;
					top-app         = <400 400 400 400 200 200  20  25>;
					rt              = <400 400 400 400 200 200  20  25>;
				};

				/* Boosting margin applied to frequency selection */
				freq_boost {       /* cpu    0  1  2  3  4  5  6  7 */
					root            = <  0  0  0  0  0  0  0  0 >;
					foreground      = <  0  0  0  0  0  0  0  0 >;
					background      = <  0  0  0  0  0  0  0  0 >;
					top-app         = <  0  0  0  0  0  0  0  0 >;
					rt              = <  0  0  0  0  0  0  0  0 >;
				};

				/* cpus allowed applied to core selection */
				cpus_allowed {
					target-sched-class = <EMS_SCHED_FAIR>;

					root		= "0-7";
					foreground 	= "0-7";
					background	= "0-7";
					top-app		= "0-7";
					rt		= "0-7";
				};

				/* gov-data used by CPUFreq governor */
				esg {			/* LIT MED BIG */
					step		= <  4   6   8 >;
					patient_mode	= < 0  0  0>;
				};

				/* Ontime Migration */
				ontime {        /* root fg bg ta rt */
					enabled  = <  0  1  0  1  0  >;

					dom_list_u {
						domain0 {
							cpus = "0-3";
							lower-boundary = <0>;
							upper-boundary = <105>;
						};
						domain1 {
							cpus = "4-5";
							lower-boundary = <106>;
							upper-boundary = <586>;
						};
						domain2 {
							cpus = "6-7";
							lower-boundary = <205>;
							upper-boundary = <1024>;
						};
					};
					dom_list_s {
						domain0 {
							cpus = "0-3";
							lower-boundary = <0>;
							upper-boundary = <51>;
						};
						domain1 {
							cpus = "4-5";
							lower-boundary = <41>;
							upper-boundary = <344>;
						};
						domain2 {
							cpus = "6-7";
							lower-boundary = <300>;
							upper-boundary = <1024>;
						};
					};
				};

				util_est {	/* root fg bg ta rt */
					enabled  = <  0  1  0  1  0  >;
				};

				prio_pinning {	/* root fg bg ta rt */
					enabled  = <  0  0  0  0  0  >;

					mask = "6-7";
					prio = <110>;
				};

				init_util {	/* root fg bg ta rt */
					ratio  = <    0  0  0  0  0  >;
				};

				frt {	   		/* LIT MED BIG */
					coverage_ratio =  < 30  30  30>;
					active_ratio =	  < 25 100 100>;
				};

				migov {
					migov_en = < 0 >;
				};
			};

			set21: set@0021{
				idx = <21>;
				desc = "balance med boost";

				/* weight (%) applied to active cpu's efficiency */
				weight {           /* cpu    0   1   2   3   4   5   6   7 */
					root            = <200 200 200 200 100 100  20  25>;
					foreground      = < 50  50  50  50 150 150 100 106>;
					background      = <200 200 200 200 100 100  20  25>;
					top-app      	= < 50  50  50  50 150 150 100 106>;
					rt              = <200 200 200 200 100 100  20  25>;
				};

				/* weight (%) applied to idle cpu's efficiency */
				idle_weight {      /* cpu     0    1    2    3   4   5   6   7 */
					root            = <400 400 400 400 200 200  20  25>;
					foreground      = <200 200 200 200 7600 7600 3800 4028>;
					background      = <400 400 400 400 200 200  20  25>;
					top-app	      	= <200 200 200 200 7600 7600 3800 4028>;
					rt              = <400 400 400 400 200 200  20  25>;
				};

				/* Boosting margin applied to frequency selection */
				freq_boost {       /* cpu    0  1  2  3  4  5  6  7 */
					root            = <  0  0  0  0  0  0  0  0 >;
					foreground      = <  0  0  0  0  0  0  0  0 >;
					background      = <  0  0  0  0  0  0  0  0 >;
					top-app         = <  0  0  0  0  0  0  0  0 >;
					rt              = <  0  0  0  0  0  0  0  0 >;
				};
			};

			set22: set@0022{
				idx = <22>;
				desc = "balance touch boost";

				/* weight (%) applied to active cpu's efficiency */
				weight {           /* cpu    0   1   2   3   4   5   6   7 */
					root            = <200 200 200 200 100 100  20  25>;
					foreground      = < 50  50  50  50 150 150 100 106>;
					background      = <200 200 200 200 100 100  20  25>;
					top-app      	= < 50  50  50  50 150 150 100 106>;
					rt              = <200 200 200 200 100 100  20  25>;
				};

				/* weight (%) applied to idle cpu's efficiency */
				idle_weight {      /* cpu     0    1    2    3   4   5   6   7 */
					root            = <400 400 400 400 200 200  20  25>;
					foreground      = <200 200 200 200 7600 7600 3800 4028>;
					background      = <400 400 400 400 200 200  20  25>;
					top-app         = <200 200 200 200 7600 7600 3800 4028>;
					rt	            = <400 400 400 400 200 200  20  25>;
				};

				freq_boost {       /* cpu    0  1  2  3  4  5  6  7 */
					root            = <  0  0  0  0  0  0  0  0 >;
					foreground      = <  0  0  0  0  0  0  0  0 >;
					background      = <  0  0  0  0  0  0  0  0 >;
					top-app         = <  0  0  0  0  0  0  0  0 >;
					rt              = <  0  0  0  0  0  0  0  0 >;
				};

				frt {	   		/* LIT MED BIG */
					coverage_ratio =  < 30  30  30>;
					active_ratio =	  < 25   3   5>;
				};
			};

			set23: set@0023{
				idx = <23>;
				desc = "balance big boost";

				sched_policy {
					policy  = <SCHED_POLICY_EFF		/* root */
						   SCHED_POLICY_PERF		/* fg */
						   SCHED_POLICY_EFF		/* bg */
						   SCHED_POLICY_PERF		/* ta */
						   SCHED_POLICY_EFF>;		/* rt */
				};

				/* weight (%) applied to active cpu's efficiency */
				weight {           /* cpu    0   1   2   3   4   5   6   7 */
					root            = <100 100 100 100 100 100 100 100>;
					foreground      = <100 100 100 100 200 200 300 300>;
					background      = <100 100 100 100 100 100 100 100>;
					top-app         = <100 100 100 100 200 200 300 300>;
					rt              = <100 100 100 100 200 200 100 100>;
				};

				freq_boost {       /* cpu    0  1  2  3  4  5  6  7 */
					root            = <  0  0  0  0  0  0  0  0 >;
					foreground      = <  0  0  0  0  0  0  0  0 >;
					background      = <  0  0  0  0  0  0  0  0 >;
					top-app         = <  0  0  0  0  0  0  0  0 >;
					rt              = <  0  0  0  0  0  0  0  0 >;
				};

				/* Ontime Migration */
				ontime {        /* root fg bg ta rt */
					enabled  = <  0  1  0  1  0  >;

					dom_list_u {
						domain0 {
							cpus = "0-3";
							lower-boundary = <0>;
							upper-boundary = <105>;
						};
						domain1 {
							cpus = "4-5";
							lower-boundary = <106>;
							upper-boundary = <586>;
						};
						domain2 {
							cpus = "6-7";
							lower-boundary = <205>;
							upper-boundary = <1024>;
						};
					};
					dom_list_s {
						domain0 {
							cpus = "0-3";
							lower-boundary = <0>;
							upper-boundary = <51>;
						};
						domain1 {
							cpus = "4-5";
							lower-boundary = <41>;
							upper-boundary = <344>;
						};
						domain2 {
							cpus = "6-7";
							lower-boundary = <300>;
							upper-boundary = <1024>;
						};
					};
				};

				prio_pinning {	/* root fg bg ta rt */
					enabled  = <  0  1  0  1  0  >;

					mask = "6-7";
					prio = <110>;
				};

				init_util {	/* root fg bg ta rt */
					ratio  = <    0  0  0  0  0  >;
				};

				frt {	   		/* LIT MED BIG */
					coverage_ratio =  < 30  30  30>;
					active_ratio =	  < 25   3   5>;
				};
			};

			set24: set@0024{
				idx = <24>;
				desc = "pinned default";

				sched_policy {
					policy  = <SCHED_POLICY_EFF		/* root */
						   SCHED_POLICY_EFF		/* fg */
						   SCHED_POLICY_EFF		/* bg */
						   SCHED_POLICY_EFF		/* ta */
						   SCHED_POLICY_EFF>;		/* rt */
				};

				/* weight (%) applied to active cpu's efficiency */
				weight {           /* cpu    0   1   2   3   4   5   6   7 */
					root            = <200 200 200 200 100 100  20  25>;
					foreground      = <200 200 200 200 100 100  20  25>;
					background      = <200 200 200 200 100 100  20  25>;
					top-app         = <200 200 200 200 100 100  20  25>;
					rt              = <200 200 200 200 100 100  20  25>;
				};

				/* weight (%) applied to idle cpu's efficiency */
				idle_weight {      /* cpu     0    1    2    3   4   5   6   7 */
					root            = <400 400 400 400 200 200  20  25>;
					foreground      = <400 400 400 400 200 200  20  25>;
					background      = <400 400 400 400 200 200  20  25>;
					top-app         = <400 400 400 400 200 200  20  25>;
					rt              = <400 400 400 400 200 200  20  25>;
				};

				/* Boosting margin applied to frequency selection */
				freq_boost {       /* cpu    0  1  2  3  4  5  6  7 */
					root            = <  0  0  0  0  0  0  0  0 >;
					foreground      = <  0  0  0  0  0  0  0  0 >;
					background      = <  0  0  0  0  0  0  0  0 >;
					top-app         = <  5  5  5  5  5  5  5  5 >;
					rt              = <  0  0  0  0  0  0  0  0 >;
				};

				/* cpus allowed applied to core selection */
				cpus_allowed {
					target-sched-class = <EMS_SCHED_FAIR>;

					root		= "0-7";
					foreground 	= "0-7";
					background	= "0-7";
					top-app		= "0-7";
					rt		= "0-7";
				};

				/* gov-data used by CPUFreq governor */
				esg {			/* LIT MED BIG */
					step		= <  4   6   8 >;
					patient_mode	= < 0  0  0>;
				};

				/* Ontime Migration */
				ontime {        /* root fg bg ta rt */
					enabled  = <  0  1  0  1  0  >;

					dom_list_u {
						domain0 {
							cpus = "0-3";
							lower-boundary = <0>;
							upper-boundary = <105>;
						};
						domain1 {
							cpus = "4-5";
							lower-boundary = <106>;
							upper-boundary = <586>;
						};
						domain2 {
							cpus = "6-7";
							lower-boundary = <205>;
							upper-boundary = <1024>;
						};
					};
					dom_list_s {
						domain0 {
							cpus = "0-3";
							lower-boundary = <0>;
							upper-boundary = <51>;
						};
						domain1 {
							cpus = "4-5";
							lower-boundary = <41>;
							upper-boundary = <344>;
						};
						domain2 {
							cpus = "6-7";
							lower-boundary = <300>;
							upper-boundary = <1024>;
						};
					};
				};

				util_est {	/* root fg bg ta rt */
					enabled  = <  0  1  0  1  0  >;
				};

				prio_pinning {	/* root fg bg ta rt */
					enabled  = <  0  0  0  0  0  >;

					mask = "6-7";
					prio = <110>;
				};

				init_util {	/* root fg bg ta rt */
					ratio  = <    0  0  0  0  0  >;
				};

				frt {	   		/* LIT MED BIG */
					coverage_ratio =  < 30  30  30>;
					active_ratio =	  < 25 100 100>;
				};

				migov {
					migov_en = < 0 >;
				};
			};

			set25: set@0025{
				idx = <25>;
				desc = "pinned med boost";

				sched_policy {
					policy  = <SCHED_POLICY_EFF		/* root */
						   SCHED_POLICY_EFF		/* fg */
						   SCHED_POLICY_EFF		/* bg */
						   SCHED_POLICY_EFF		/* ta */
						   SCHED_POLICY_EFF>;		/* rt */
				};

				/* weight (%) applied to active cpu's efficiency */
				weight {           /* cpu    0   1   2   3   4   5   6   7 */
					root            = <200 200 200 200 100 100  20  25>;
					foreground      = < 50  50  50  50 150 150 100 106>;
					background      = <200 200 200 200 100 100  20  25>;
					top-app      	= < 50  50  50  50 150 150 100 106>;
					rt              = <200 200 200 200 100 100  20  25>;
				};

				/* cpus allowed applied to core selection */
				cpus_allowed {
					target-sched-class = <EMS_SCHED_FAIR>;

					root		= "0-7";
					foreground 	= "0-7";
					background	= "0-7";
					top-app		= "0-7";
					rt		= "0-7";
				};

				/* weight (%) applied to idle cpu's efficiency */
				idle_weight {      /* cpu     0    1    2    3   4   5   6   7 */
					root            = <400 400 400 400 200 200  20  25>;
					foreground      = <200 200 200 200 7600 7600 3800 4028>;
					background      = <400 400 400 400 200 200  20  25>;
					top-app	      	= <200 200 200 200 7600 7600 3800 4028>;
					rt              = <400 400 400 400 200 200  20  25>;
				};

				/* Boosting margin applied to frequency selection */
				freq_boost {       /* cpu    0  1  2  3  4  5  6  7 */
					root            = <  0  0  0  0  0  0  0  0 >;
					foreground      = <  0  0  0  0  0  0  0  0 >;
					background      = <  0  0  0  0  0  0  0  0 >;
					top-app         = <  5  5  5  5  5  5  5  5 >;
					rt              = <  0  0  0  0  0  0  0  0 >;
				};

				/* Ontime Migration */
				ontime {        /* root fg bg ta rt */
					enabled  = <  0  1  0  1  0  >;

					dom_list_u {
						domain0 {
							cpus = "0-3";
							lower-boundary = <0>;
							upper-boundary = <105>;
						};
						domain1 {
							cpus = "4-5";
							lower-boundary = <106>;
							upper-boundary = <586>;
						};
						domain2 {
							cpus = "6-7";
							lower-boundary = <205>;
							upper-boundary = <1024>;
						};
					};
					dom_list_s {
						domain0 {
							cpus = "0-3";
							lower-boundary = <0>;
							upper-boundary = <51>;
						};
						domain1 {
							cpus = "6-7";
							lower-boundary = <41>;
							upper-boundary = <200>;
						};
						domain2 {
							cpus = "4-5";
							lower-boundary = <100>;
							upper-boundary = <1024>;
						};
					};
				};
			};

			set26: set@0026{
				idx = <26>;
				desc = "pinned touch boost";

				/* weight (%) applied to active cpu's efficiency */
				weight {           /* cpu    0   1   2   3   4   5   6   7 */
					root            = <200 200 200 200 100 100  20  25>;
					foreground      = < 50  50  50  50 150 150 100 106>;
					background      = <200 200 200 200 100 100  20  25>;
					top-app      	= < 50  50  50  50 150 150 100 106>;
					rt              = <200 200 200 200 100 100  20  25>;
				};

				/* weight (%) applied to idle cpu's efficiency */
				idle_weight {      /* cpu     0    1    2    3   4   5   6   7 */
					root            = <400 400 400 400 200 200  20  25>;
					foreground      = <200 200 200 200 7600 7600 3800 4028>;
					background      = <400 400 400 400 200 200  20  25>;
					top-app         = <200 200 200 200 7600 7600 3800 4028>;
					rt	            = <400 400 400 400 200 200  20  25>;
				};

				/* Boosting margin applied to frequency selection */
				freq_boost {       /* cpu    0  1  2  3  4  5  6  7 */
					root            = <  0  0  0  0  0  0  0  0 >;
					foreground      = <  0  0  0  0  0  0  0  0 >;
					background      = <  0  0  0  0  0  0  0  0 >;
					top-app         = < 20 20 20 20 20 20 20 20 >;
					rt              = <  0  0  0  0  0  0  0  0 >;
				};

				/* cpus allowed applied to core selection */
				cpus_allowed {
					target-sched-class = <EMS_SCHED_FAIR>;

					root		= "0-7";
					foreground 	= "0-7";
					background	= "0-7";
					top-app		= "0-7";
					rt		= "0-7";
				};

				/* Ontime Migration */
				ontime {        /* root fg bg ta rt */
					enabled  = <  0  1  0  1  0  >;

					dom_list_u {
						domain0 {
							cpus = "0-3";
							lower-boundary = <0>;
							upper-boundary = <105>;
						};
						domain1 {
							cpus = "4-5";
							lower-boundary = <106>;
							upper-boundary = <586>;
						};
						domain2 {
							cpus = "6-7";
							lower-boundary = <205>;
							upper-boundary = <1024>;
						};
					};
					dom_list_s {
						domain0 {
							cpus = "0-3";
							lower-boundary = <0>;
							upper-boundary = <51>;
						};
						domain1 {
							cpus = "6-7";
							lower-boundary = <41>;
							upper-boundary = <200>;
						};
						domain2 {
							cpus = "4-5";
							lower-boundary = <100>;
							upper-boundary = <1024>;
						};
					};
				};

				frt {	   		/* LIT MED BIG */
					coverage_ratio =  < 30  30  30>;
					active_ratio =	  < 25   3   5>;
				};
			};

			set27: set@0027{
				idx = <27>;
				desc = "pinned big boost";

				sched_policy {
					policy  = <SCHED_POLICY_EFF		/* root */
						   SCHED_POLICY_PERF		/* fg */
						   SCHED_POLICY_EFF		/* bg */
						   SCHED_POLICY_PERF		/* ta */
						   SCHED_POLICY_EFF>;		/* rt */
				};

				/* weight (%) applied to active cpu's efficiency */
				weight {           /* cpu    0   1   2   3   4   5   6   7 */
					root            = <100 100 100 100 100 100 100 100>;
					foreground      = <100 100 100 100 200 200 300 300>;
					background      = <100 100 100 100 100 100 100 100>;
					top-app         = <100 100 100 100 200 200 300 300>;
					rt              = <100 100 100 100 200 200 100 100>;
				};

				freq_boost {       /* cpu    0  1  2  3  4  5  6  7 */
					root            = <  0  0  0  0  0  0  0  0 >;
					foreground      = <  0  0  0  0  0  0  0  0 >;
					background      = <  0  0  0  0  0  0  0  0 >;
					top-app         = <  0  0  0  0  0  0  0  0 >;
					rt              = <  0  0  0  0  0  0  0  0 >;
				};

				/* Ontime Migration */
				ontime {        /* root fg bg ta rt */
					enabled  = <  0  1  0  1  0  >;

					dom_list_u {
						domain0 {
							cpus = "0-3";
							lower-boundary = <0>;
							upper-boundary = <105>;
						};
						domain1 {
							cpus = "4-5";
							lower-boundary = <106>;
							upper-boundary = <586>;
						};
						domain2 {
							cpus = "6-7";
							lower-boundary = <205>;
							upper-boundary = <1024>;
						};
					};
					dom_list_s {
						domain0 {
							cpus = "0-3";
							lower-boundary = <0>;
							upper-boundary = <51>;
						};
						domain1 {
							cpus = "4-5";
							lower-boundary = <41>;
							upper-boundary = <344>;
						};
						domain2 {
							cpus = "6-7";
							lower-boundary = <300>;
							upper-boundary = <1024>;
						};
					};
				};

				prio_pinning {	/* root fg bg ta rt */
					enabled  = <  0  1  0  1  0  >;

					mask = "6-7";
					prio = <110>;
				};

				init_util {	/* root fg bg ta rt */
					ratio  = <    0  0  0  0  0  >;
				};

				frt {	   		/* LIT MED BIG */
					coverage_ratio =  < 30  30  30>;
					active_ratio =	  < 25   3   5>;
				};
			};

			set28: set@0028{
				idx = <28>;
				desc = "game-mode default";

				sched_policy {
					policy  = <SCHED_POLICY_ENERGY		/* root */
						   SCHED_POLICY_ENERGY		/* fg */
						   SCHED_POLICY_ENERGY		/* bg */
						   SCHED_POLICY_ENERGY		/* ta */
						   SCHED_POLICY_ENERGY>;	/* rt */
				};

				/* weight (%) applied to active cpu's efficiency */
				weight {           /* cpu    0   1   2   3   4   5   6   7 */
					root            = <100 100 100 100 100 100  100  100>;
					foreground      = <100 100 100 100 100 100  100  100>;
					background      = <100 100 100 100 100 100  100  100>;
					top-app         = <100 100 100 100 100 100  100  100>;
					rt              = <100 100 100 100 100 100  100  100>;
				};

				/* weight (%) applied to idle cpu's efficiency */
				idle_weight {      /* cpu    0   1   2   3   4   5   6   7 */
					root            = <100 100 100 100 100 100  100  100>;
					foreground      = <100 100 100 100 100 100  100  100>;
					background      = <100 100 100 100 100 100  100  100>;
					top-app         = <100 100 100 100 100 100  100  100>;
					rt              = <100 100 100 100 100 100  100  100>;
				};

				/* Boosting margin applied to frequency selection */
				freq_boost {       /* cpu    0  1  2  3  4  5  6  7 */
					root            = <  0  0  0  0  0  0  0  0 >;
					foreground      = <  0  0  0  0  0  0  0  0 >;
					background      = <  0  0  0  0  0  0  0  0 >;
					top-app         = <  0  0  0  0  0  0  0  0 >;
					rt              = <  0  0  0  0  0  0  0  0 >;
				};

				/* cpus allowed applied to core selection */
				cpus_allowed {
					target-sched-class = <EMS_SCHED_FAIR>;

					root		= "0-7";
					foreground	= "0-7";
					background	= "0-7";
					top-app		= "0-7";
					rt		= "0-7";
				};

				/* gov-data used by CPUFreq governor */
				esg {			/* LIT MED BIG */
					step		= <  6   6   6 >;
					patient_mode	= <  4   4   4 >;
				};

				/* Ontime Migration */
				ontime {        /* root fg bg ta rt */
					enabled  = <  0  1  0  1  0  >;

					dom_list_u {
						domain0 {
							cpus = "0-3";
							lower-boundary = <0>;
							upper-boundary = <105>;
						};
						domain1 {
							cpus = "4-5";
							lower-boundary = <106>;
							upper-boundary = <586>;
						};
						domain2 {
							cpus = "6-7";
							lower-boundary = <205>;
							upper-boundary = <1024>;
						};
					};
					dom_list_s {
						domain0 {
							cpus = "0-3";
							lower-boundary = <0>;
							upper-boundary = <51>;
						};
						domain1 {
							cpus = "4-7";
							lower-boundary = <41>;
							upper-boundary = <1024>;
						};
					};
				};
				util_est {	/* root fg bg ta rt */
					enabled  = <  0  1  0  1  0  >;
				};

				prio_pinning {	/* root fg bg ta rt */
					enabled  = <  0  0  0  0  0  >;

					mask = "6-7";
					prio = <110>;
				};

				init_util {	/* root fg bg ta rt */
					ratio  = <   25 25 25 25 25  >;
				};

				frt {			/* LIT MED BIG */
					coverage_ratio =  < 30  30  30>;
					active_ratio =	  < 100 100 100>;
				};

				migov {
					migov_en = < 1 >;
				};
			};
			set29: set@0029{
				idx = <29>;
				desc = "game-mode med boost";
			};
			set30: set@0030{
				idx = <30>;
				desc = "game-mode touch boost";
			};
			set31: set@0031{
				idx = <31>;
				desc = "game-mode big boost";

				sched_policy {
					policy  = <SCHED_POLICY_EFF		/* root */
						   SCHED_POLICY_PERF		/* fg */
						   SCHED_POLICY_EFF		/* bg */
						   SCHED_POLICY_PERF		/* ta */
						   SCHED_POLICY_EFF>;		/* rt */
				};

				/* weight (%) applied to active cpu's efficiency */
				weight {           /* cpu    0   1   2   3   4   5   6   7 */
					root            = <100 100 100 100 100 100 100 100>;
					foreground      = <100 100 100 100 200 200 300 300>;
					background      = <100 100 100 100 100 100 100 100>;
					top-app         = <100 100 100 100 200 200 300 300>;
					rt              = <100 100 100 100 200 200 100 100>;
				};

				/* weight (%) applied to idle cpu's efficiency */
				idle_weight {      /* cpu    0   1   2   3   4   5   6   7 */
					root            = <200 200 200 200 400 400  40  50>;
					foreground      = <200 200 200 200 400 400  40  50>;
					background      = <200 200 200 200 400 400  40  50>;
					top-app         = <200 200 200 200 400 400  40  50>;
					rt              = <200 200 200 200 400 400  40  50>;
				};

				/* Boosting margin applied to frequency selection */
				freq_boost {       /* cpu    0  1  2  3  4  5  6  7 */
					root            = <  0  0  0  0  0  0  0  0 >;
					foreground      = <  0  0  0  0  0  0  0  0 >;
					background      = <  0  0  0  0  0  0  0  0 >;
					top-app         = <  5  5  5  5  5  5  5  5 >;
					rt              = <  0  0  0  0  0  0  0  0 >;
				};

				/* cpus allowed applied to core selection */
				cpus_allowed {
					target-sched-class = <EMS_SCHED_FAIR>;

					root		= "0-7";
					foreground 	= "0-7";
					background	= "0-7";
					top-app		= "0-7";
					rt		= "0-7";
				};

				/* gov-data used by CPUFreq governor */
				esg {			/* LIT MED BIG */
					step		= <  4   6   8 >;
					patient_mode	= <  0   0   0 >;
				};

				/* Ontime Migration */
				ontime {        /* root fg bg ta rt */
					enabled  = <  0  1  0  1  0  >;

					dom_list_u {
						domain0 {
							cpus = "0-3";
							lower-boundary = <0>;
							upper-boundary = <105>;
						};
						domain1 {
							cpus = "4-5";
							lower-boundary = <106>;
							upper-boundary = <586>;
						};
						domain2 {
							cpus = "6-7";
							lower-boundary = <205>;
							upper-boundary = <1024>;
						};

					};
					dom_list_s {
						domain0 {
							cpus = "0-3";
							lower-boundary = <0>;
							upper-boundary = <51>;
						};
						domain1 {
							cpus = "4-5";
							lower-boundary = <41>;
							upper-boundary = <344>;
						};
						domain2 {
							cpus = "6-7";
							lower-boundary = <300>;
							upper-boundary = <1024>;
						};
					};
				};

				util_est {	/* root fg bg ta rt */
					enabled  = <  0  1  0  1  0  >;
				};

				prio_pinning {	/* root fg bg ta rt */
					enabled  = <  0  0  0  1  0  >;

					mask = "6-7";
					prio = <110>;
				};

				init_util {	/* root fg bg ta rt */
					ratio  = <    0  0  0  0  0  >;
				};

				frt {	   		/* LIT MED BIG */
					coverage_ratio =  < 30  30  30>;
					active_ratio =	  < 25   3   5>;
				};

				migov {
					migov_en = < 0 >;
				};
			};
		};
	};
};
